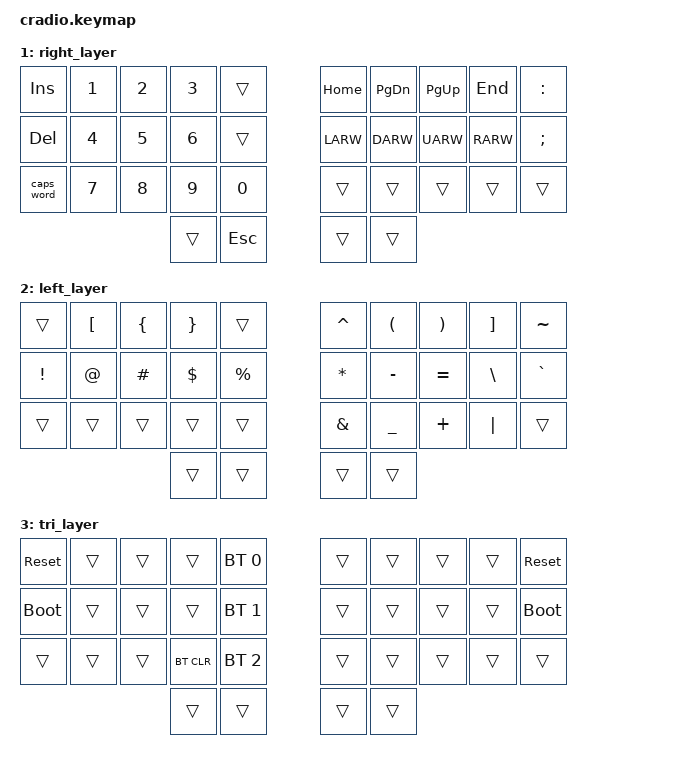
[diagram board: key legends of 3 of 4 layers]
// Copyright (c) 2022 The ZMK Contributors
// SPDX-License-Identifier: MIT

#include <behaviors.dtsi>
#include <dt-bindings/zmk/keys.h>
#include <dt-bindings/zmk/bt.h>

#include "../zmk-nodefree-config/helper.h"
#include "../zmk-nodefree-config/keypos_def/keypos_34keys.h"


#define KEYS_L LT0 LT1 LT2 LT3 LT4 LM0 LM1 LM2 LM3 LM4 LB0 LB1 LB2 LB3 LB4  // left hand
#define KEYS_R RT0 RT1 RT2 RT3 RT4 RM0 RM1 RM2 RM3 RM4 RB0 RB1 RB2 RB3 RB4  // right hand
#define THUMBS LH1 LH0 RH0 RH1                                      // thumbs
#define QUICK_TAP_MS 175

// Home row mods macro
#define HRML(k1,k2,k3,k4) &hml LSHFT k1  &hml LALT k2  &hml LCTRL k3  &hml LGUI k4
#define HRMR(k1,k2,k3,k4) &hmr RGUI k1  &hmr RCTRL k2  &hmr RALT k3  &hmr RSHFT k4

/ {
    behaviors {
        ht: hold_tap_ht {
            label = "hold_tap";
            compatible = "zmk,behavior-hold-tap";
            #binding-cells = <2>;
            flavor = "tap-preferred";
            tapping-term-ms = <220>;
            quick-tap-ms = <150>;
            global-quick-tap;
            bindings = <&kp>, <&kp>;
        };

        hml: hold_tap_hml {
            label = "hml";
            compatible = "zmk,behavior-hold-tap";
            #binding-cells = <2>;
            flavor = "balanced";
            tapping-term-ms = <280>;
            quick-tap-ms = <QUICK_TAP_MS>;
            bindings = <&kp>, <&kp>;
            hold-trigger-key-positions = <KEYS_R THUMBS>;
            hold-trigger-on-release;
        };

        hmr: hold_tap_hmr {
            label = "hmr";
            compatible = "zmk,behavior-hold-tap";
            #binding-cells = <2>;
            flavor = "balanced";
            tapping-term-ms = <280>;
            quick-tap-ms = <QUICK_TAP_MS>;
            bindings = <&kp>, <&kp>;
            hold-trigger-key-positions = <KEYS_L THUMBS>;
            hold-trigger-on-release;
        };
    };

    conditional_layers {
        compatible = "zmk,conditional-layers";
        tri_layer {
            if-layers = <1 2>;
            then-layer = <3>;
        };
    };

    keymap {
        compatible = "zmk,keymap";
        default_layer {
            bindings = <
        //╭──────────┬──────────┬──────────┬──────────┬──────────╮   ╭──────────┬──────────┬──────────┬──────────┬──────────╮
        //│  Q       │  W       │  E       │  R       │  T       │   │  Y       │  U       │  I       │  O       │  P       │
            &kp Q      &kp W      &kp E      &kp R      &kp T          &kp Y      &kp U      &kp I      &kp O      &kp P
        //├──────────┼──────────┼──────────┼──────────┼──────────┤   ├──────────┼──────────┼──────────┼──────────┼──────────┤
        //│  A       │  S       │  D       │  F       │  G       │   │  H       │  J       │  K       │  L       │ ' "      │
            HRML(A,        S,         D,         F)     &kp G          &kp H      HRMR(J,        K,         L,        SQT)
        //├──────────┼──────────┼──────────┼──────────┼──────────┤   ├──────────┼──────────┼──────────┼──────────┼──────────┤
        //│  Z       │  X       │  C       │  V       │  B       │   │  N       │  M       │ , <      │ . >      │ / ?      │
            &kp Z      &kp X      &kp C      &kp V      &kp B          &kp N      &kp M      &kp COMMA  &kp DOT    &kp FSLH
        //╰──────────┴──────────┴──────────┼──────────┼──────────┤   ├──────────┼──────────┼──────────┴──────────┴──────────╯
                                            &lt 2 TAB   &kp ENTER     &kp SPACE  &lt 1 BSPC
        //                                 ╰──────────┴──────────╯   ╰──────────┴──────────╯
            >;
        };

        right_layer {
            bindings = <
        //╭──────────┬──────────┬──────────┬──────────┬──────────╮   ╭──────────┬──────────┬──────────┬──────────┬──────────╮
        //│ INSERT   │  1       │  2       │  3       │          │   │ HOME     │ PAGE DN  │ PAGE UP  │ END      │  :       │
            &kp INS    &kp N1     &kp N2     &kp N3     &trans         &kp HOME   &kp PG_DN  &kp PG_UP  &kp END    &kp COLON
        //├──────────┼──────────┼──────────┼──────────┼──────────┤   ├──────────┼──────────┼──────────┼──────────┼──────────┤
        //│ DELETE   │  4       │  5       │  6       │          │   │ LEFT     │ DOWN     │ UP       │ RIGHT    │  ;       │
            &kp DEL    &kp N4     &kp N5     &kp N6     &trans         &kp LARW   &kp DARW   &kp UARW   &kp RARW   &kp SEMI
        //├──────────┼──────────┼──────────┼──────────┼──────────┤   ├──────────┼──────────┼──────────┼──────────┼──────────┤
        //│ CAPS     │  7       │  8       │  9       │  0       │   │          │          │          │          │          │
           &caps_word  &kp N7     &kp N8     &kp N9     &kp N0         &trans     &trans     &trans     &trans     &trans
        //╰──────────┴──────────┴──────────┼──────────┼──────────┤   ├──────────┼──────────┼──────────┴──────────┴──────────╯
                                             &trans     &kp ESC        &trans     &trans
        //                                 ╰──────────┴──────────╯   ╰──────────┴──────────╯
            >;
        };

        left_layer {
            bindings = <
        //╭──────────┬──────────┬──────────┬──────────┬──────────╮   ╭──────────┬──────────┬──────────┬──────────┬──────────╮
        //│          │  [       │  {       │  }       │          │   │  ^       │  (       │  )       │  ]       │  ~       │
            &trans     &kp LBKT   &kp LBRC   &kp RBRC   &trans         &kp CARET  &kp LPAR   &kp RPAR   &kp RBKT   &kp TILDE
        //├──────────┼──────────┼──────────┼──────────┼──────────┤   ├──────────┼──────────┼──────────┼──────────┼──────────┤
        //│  !       │  @       │  #       │  $       │  %       │   │  *       │  -       │  =       │  \       │  `       │
            &kp EXCL   &kp AT     &kp HASH   &kp DLLR   &kp PRCNT      &kp ASTRK  &kp MINUS  &kp EQUAL  &kp BSLH   &kp GRAVE
        //├──────────┼──────────┼──────────┼──────────┼──────────┤   ├──────────┼──────────┼──────────┼──────────┼──────────┤
        //│          │          │          │          │          │   │  &       │  _       │  +       │  │       │          │
            &trans     &trans     &trans     &trans     &trans         &kp AMPS   &kp UNDER  &kp PLUS   &kp PIPE   &trans
        //╰──────────┴──────────┴──────────┼──────────┼──────────┤   ├──────────┼──────────┼──────────┴──────────┴──────────╯
                                             &trans     &trans         &trans     &trans
        //                                 ╰──────────┴──────────╯   ╰──────────┴──────────╯
            >;
        };

        tri_layer {
            bindings = <
        //╭──────────┬──────────┬──────────┬──────────┬──────────╮   ╭──────────┬──────────┬──────────┬──────────┬──────────╮
        //│ RESET    │          │          │          │PROFILE 0 │   │          │          │          │          │  RESET   │
           &sys_reset  &trans     &trans     &trans    &bt BT_SEL 0    &trans     &trans     &trans     &trans    &sys_reset
        //├──────────┼──────────┼──────────┼──────────┼──────────┤   ├──────────┼──────────┼──────────┼──────────┼──────────┤
        //│BOOTLOADER│          │          │          │PROFILE 1 │   │          │          │          │          │BOOTLOADER│
          &bootloader  &trans     &trans     &trans    &bt BT_SEL 1    &trans     &trans     &trans     &trans    &bootloader
        //├──────────┼──────────┼──────────┼──────────┼──────────┤   ├──────────┼──────────┼──────────┼──────────┼──────────┤
        //│          │          │          │ CLEAR BT │PROFILE 2 │   │          │          │          │          │          │
            &trans     &trans     &trans    &bt BT_CLR &bt BT_SEL 2    &trans     &trans     &trans     &trans     &trans
        //╰──────────┴──────────┴──────────┼──────────┼──────────┤   ├──────────┼──────────┼──────────┴──────────┴──────────╯
                                             &trans     &trans         &trans     &trans
        //                                 ╰──────────┴──────────╯   ╰──────────┴──────────╯
            >;
        };
    };
};
